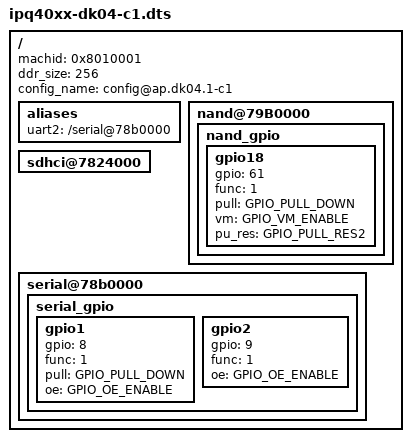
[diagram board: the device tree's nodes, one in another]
/*
 * Copyright (c) 2016, The Linux Foundation. All rights reserved.
 *
 * This program is free software; you can redistribute it and/or modify
 * it under the terms of the GNU General Public License version 2 and
 * only version 2 as published by the Free Software Foundation.
 *
 * This program is distributed in the hope that it will be useful,
 * but WITHOUT ANY WARRANTY; without even the implied warranty of
 * MERCHANTABILITY or FITNESS FOR A PARTICULAR PURPOSE.  See the
 * GNU General Public License for more details.
 */

/dts-v1/;
#include "ipq40xx-dk04.dtsi"
#include "nand_gpio.dtsi"
/ {
	machid = <0x8010001>;
	ddr_size = <256>;
	config_name = "config@ap.dk04.1-c1";

	aliases {
		uart2 = "/serial@78b0000";
	};

	nand@79B0000 {
		status = "ok";
		nand_gpio {
			gpio18 {
				gpio = <61>;
				func = <1>;
				pull = <GPIO_PULL_DOWN>;
				vm = <GPIO_VM_ENABLE>;
				pu_res = <GPIO_PULL_RES2>;
			};
		};
	};

	sdhci@7824000 {
		status = "okay";
	};
	serial@78b0000 {
		status = "ok";
		serial_gpio {
			gpio1 {
				gpio = <8>;
				func = <1>;
				pull = <GPIO_PULL_DOWN>;
				oe = <GPIO_OE_ENABLE>;
			};

			gpio2 {
				gpio = <9>;
				func = <1>;
				oe = <GPIO_OE_ENABLE>;
			};
		};
	};

};
